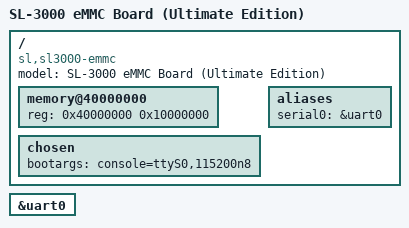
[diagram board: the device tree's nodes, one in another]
/dts-v1/;

/* SoC Base Layer */
#include "mt7981b.dtsi"
#include <dt-bindings/gpio/gpio.h>
#include <dt-bindings/input/input.h>

/ {
    model = "SL-3000 eMMC Board (Ultimate Edition)";
    compatible = "sl,sl3000-emmc", "mediatek,mt7981";

    memory@40000000 {
        device_type = "memory";
        reg = <0x40000000 0x10000000>; /* 256MB */
    };

    chosen {
        bootargs = "console=ttyS0,115200n8";
    };

    aliases {
        serial0 = &uart0;
    };
};

/* UART */
&uart0 {
    status = "okay";
};
